# FX1 register map
Vendor: FTEL; File version: VP_FX1_V3.0_ISP_1.07
Registers are 32-bit, read-write, reset 0x0 unless marked. A register's access mark holds for its fields unless they carry their own. Offsets are from the block's base; [hi:lo] are bit positions; {n}, {i} and the like mark numbered series; 'fields as' and 'values as' point back to an identical list.

## MIPI_CSI2 — MIPI CSI-2 RX Controller (FTEL MAS v1.4 / HAS v1.2, CSR v1.4). Chỉ có khi VP bật --camera. Base là placeholder VP; 4 KiB aperture, giải mã 0x00-0xFF, 0x100-0xFFF trả DECERR. Lệch so với VP fx1_csi2_regs.h (workbook cũ): IP_VERSION, STREAM_CONFIG reset/bit2, BUFFER_STATUS bit19, DMA_ATTR reset, META_AREA_SIZE, TPG_CONTROL[5:4].
Base 0x11040000
0x00 IP_VERSION ro reset 0x10200 — IP identifier and version: major [31:16], minor [15:8], patch [7:0]. [access=ro]
  [31:0] IP_VERSION — 0x0001_0200 = v1.2.0 (MAS v1.4 param IP_VERSION). [access=ro]
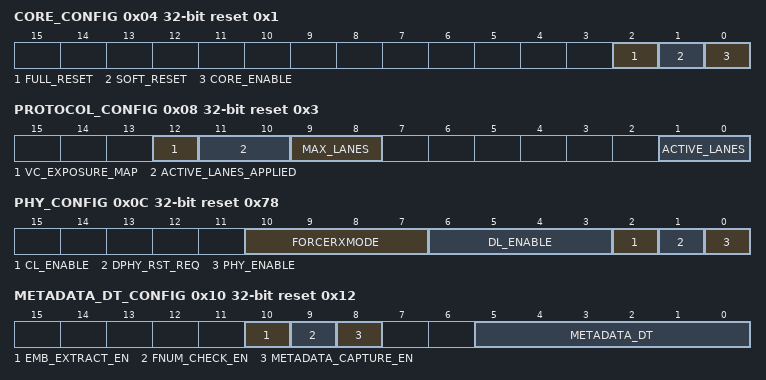
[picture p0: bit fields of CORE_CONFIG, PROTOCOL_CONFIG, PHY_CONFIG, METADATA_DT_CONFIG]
0x04 CORE_CONFIG reset 0x1 — Core control. [access=mixed]
  [2] FULL_RESET wo — Self-clearing. Resets D-PHY + datapath + register file via PHY Reset Sequencer. [access=wo]
  [1] SOFT_RESET — Level datapath reset, config preserved. Needs running rxbyteclkhs to reach Lane Mgmt. [access=rw]
  [0] CORE_ENABLE — Global core enable. Low: Packet FSM idle, per-VC context cleared, open captures dropped. [access=rw]
0x08 PROTOCOL_CONFIG reset 0x3 — Protocol configuration. [access=mixed]
  [12] VC_EXPOSURE_MAP — 0: VC0=Long, VC1=Short; 1: swapped. Applied to TID and lead channel. [access=rw]
  [11:10] ACTIVE_LANES_APPLIED ro — Lane count in use inside the datapath (read-back). [access=ro]
  [9:8] MAX_LANES ro — Build parameter MAX_LANES (reads parameter; counted as 0 in reset value). [access=ro]
  [1:0] ACTIVE_LANES — 00=1 lane, 01=2 lanes, 11=4 lanes, 10 reserved. Adopted only in Lane Mgmt ST_IDLE. [access=rw]
0x0C PHY_CONFIG reset 0x78 — D-PHY configuration. [access=mixed]
  [10:7] FORCERXMODE — Per-lane force-receive-mode, debug/bring-up only. [access=rw]
  [6:3] DL_ENABLE — Data-lane enables, bit 3 = lane 0 .. bit 6 = lane 3. [access=rw]
  [2] CL_ENABLE — Clock-lane enable. [access=rw]
  [1] DPHY_RST_REQ wo — Self-clearing. Starts PHY Reset Sequencer (phy_core_rst >= 40 core_clk). [access=wo]
  [0] PHY_ENABLE — D-PHY enable; when 0, cl_enable and all dl_enable outputs are deasserted. [access=rw]
0x10 METADATA_DT_CONFIG reset 0x12 — Metadata Data Type configuration. [access=rw]
  [10] EMB_EXTRACT_EN — Enable embedded-data field extractor. [access=rw]
  [9] FNUM_CHECK_EN — Enable frame-number sequence check. [access=rw]
  [8] METADATA_CAPTURE_EN — Enable embedded-data routing/capture. [access=rw]
  [5:0] METADATA_DT — Data Type routed to embedded-data path. Must not be 0x10/0x11/0x2B/0x2C. [access=rw]
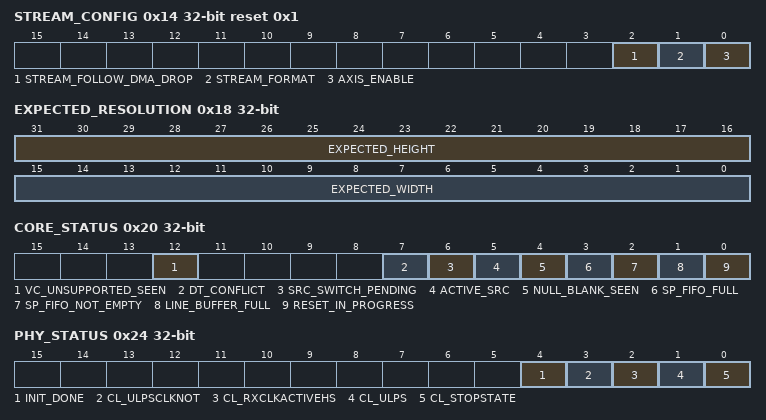
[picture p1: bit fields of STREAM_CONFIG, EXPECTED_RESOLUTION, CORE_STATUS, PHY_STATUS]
0x14 STREAM_CONFIG reset 0x1 — Stream output configuration. [access=rw]
  [2] STREAM_FOLLOW_DMA_DROP — 1: a capture dropped by DMA alone is also skipped on the stream path. [access=rw]
  [1] STREAM_FORMAT — 0 = packed RAW10/RAW12 (bypass), 1 = RAW16. Change only while AXIS_ENABLE = 0. [access=rw]
  [0] AXIS_ENABLE — Enable AXI4-Stream path towards the ISP. [access=rw]
0x18 EXPECTED_RESOLUTION — Expected resolution, reference of the resolution check. [access=rw]
  [31:16] EXPECTED_HEIGHT — Expected active height (lines). [access=rw]
  [15:0] EXPECTED_WIDTH — Expected active width (pixels). [access=rw]
0x20 CORE_STATUS ro — Core status. [access=ro]
  [12] VC_UNSUPPORTED_SEEN — Sticky: packet on unsupported Virtual Channel dropped. [access=ro]
  [7] DT_CONFLICT — Sticky: METADATA_DT programmed to a fixed-meaning Data Type. [access=ro]
  [6] SRC_SWITCH_PENDING — Source switch in progress. [access=ro]
  [5] ACTIVE_SRC — 0 = sensor path, 1 = TPG. [access=ro]
  [4] NULL_BLANK_SEEN — Sticky: Null/Blanking long packet dropped. [access=ro]
  [3] SP_FIFO_FULL — Generic Short Packet FIFO full. [access=ro]
  [2] SP_FIFO_NOT_EMPTY — Generic Short Packet FIFO not empty. [access=ro]
  [1] LINE_BUFFER_FULL — Line Buffer fill >= FULL_WATERMARK (raw level). [access=ro]
  [0] RESET_IN_PROGRESS — PHY Reset Sequencer running or SOFT_RESET set. [access=ro]
0x24 PHY_STATUS ro — D-PHY clock lane status. [access=ro]
  [4] INIT_DONE — D-PHY initialisation done (observability only). [access=ro]
  [3] CL_ULPSCLKNOT — Clock lane ULPS line indication (reads 1 in ULPS). [access=ro]
  [2] CL_RXCLKACTIVEHS — HS clock active (rxbyteclkhs running). [access=ro]
  [1] CL_ULPS — Clock lane in ULPS (inverse of cl_ulpsactivenot). [access=ro]
  [0] CL_STOPSTATE — Clock lane in Stop State. [access=ro]
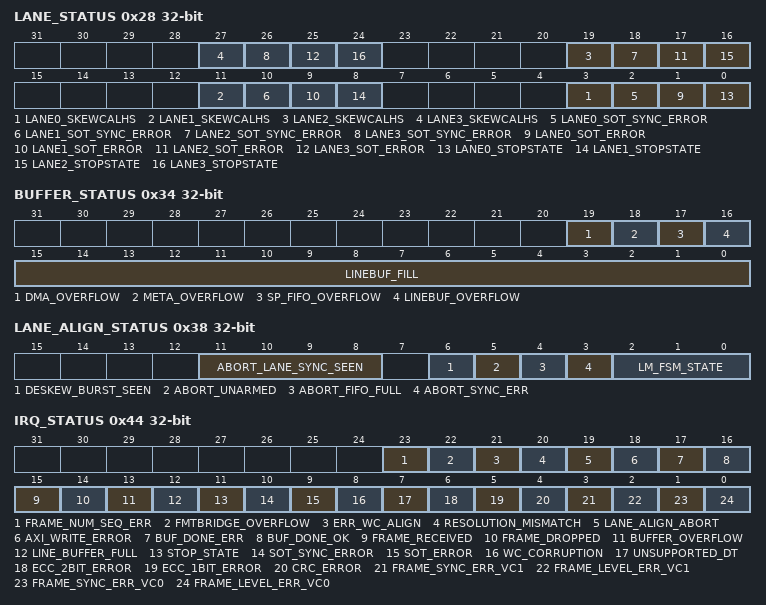
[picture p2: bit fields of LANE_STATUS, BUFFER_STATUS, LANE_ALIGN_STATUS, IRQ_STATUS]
0x28 LANE_STATUS ro — Per-lane status, lane x at bits [8x+3:8x]. SOT errors sticky, cleared by SOFT_RESET. [access=ro]
  [8n+3] LANE{n}_SKEWCALHS (n=0..3) — Lane {n} receiving deskew calibration. [access=ro]
  [8n+2] LANE{n}_SOT_SYNC_ERROR (n=0..3) — Lane {n} errsotsynchs seen (sticky). [access=ro]
  [8n+1] LANE{n}_SOT_ERROR (n=0..3) — Lane {n} errsoths seen (sticky). [access=ro]
  [8n] LANE{n}_STOPSTATE (n=0..3) — Lane {n} in Stop State. [access=ro]
0x2C PACKET_COUNT ro — Long packets whose header passed ECC; wraps at 2^32. [access=ro]
  [31:0] PACKET_COUNT — [access=ro]
0x30 FRAME_COUNT ro — Captures that have ended, dropped or not. [access=ro]
  [31:0] FRAME_COUNT — [access=ro]
0x34 BUFFER_STATUS ro — Buffer status; overflow bits sticky, cleared by reset only. [access=ro]
  [19] DMA_OVERFLOW — DMA RAW FIFO/line/region overflow (MAS v1.4). [access=ro]
  [18] META_OVERFLOW — Embedded payload word lost on metadata path. [access=ro]
  [17] SP_FIFO_OVERFLOW — Generic short packet dropped on full FIFO. [access=ro]
  [16] LINEBUF_OVERFLOW — Line Buffer write refused. [access=ro]
  [15:0] LINEBUF_FILL — Line Buffer fill level (0..2048). [access=ro]
0x38 LANE_ALIGN_STATUS ro — Lane alignment status. [access=ro]
  [11:8] ABORT_LANE_SYNC_SEEN — Per-lane sync_seen snapshot at abort; 0 = failing lane. [access=ro]
  [6] DESKEW_BURST_SEEN — Sticky: deskew burst classified and skipped. [access=ro]
  [5] ABORT_UNARMED — Last abort caused by burst closing while unarmed. [access=ro]
  [4] ABORT_FIFO_FULL — Last abort caused by PHY Delay FIFO full while unarmed. [access=ro]
  [3] ABORT_SYNC_ERR — Last abort caused by errsotsynchs. [access=ro]
  [2:0] LM_FSM_STATE — Burst FSM: 0 IDLE, 1 ARMING, 2 ALIGNED, 3 DRAIN, 4 ABORT. [access=ro]
0x40 GLOBAL_IRQ_ENABLE — Global interrupt enable. [access=rw]
  [0] GLOBAL_ENABLE — Master enable of csi2_irq. [access=rw]
0x44 IRQ_STATUS write-1-clears — Interrupt status, 24 sources, write 1 to clear; set wins over clear. Write response held until cleared bits read 0 (<= IRQ_CLR_TIMEOUT). [access=w1c]
  [23] FRAME_NUM_SEQ_ERR write-1-clears — Sensor frame number did not advance by one. [access=w1c]
  [22] FMTBRIDGE_OVERFLOW write-1-clears — Format Bridge output beat lost. [access=w1c]
  [21] ERR_WC_ALIGN write-1-clears — Line ended mid pixel-packing unit. [access=w1c]
  [20] RESOLUTION_MISMATCH write-1-clears — Frame geometry differs from EXPECTED_RESOLUTION. [access=w1c]
  [19] LANE_ALIGN_ABORT write-1-clears — Lane Management discarded a burst. [access=w1c]
  [18] AXI_WRITE_ERROR write-1-clears — DMA write got SLVERR/DECERR. [access=w1c]
  [17] BUF_DONE_ERR write-1-clears — Ping-pong buffer released as SW_OWNED_ERROR. [access=w1c]
  [16] BUF_DONE_OK write-1-clears — Ping-pong buffer released as SW_OWNED_VALID. [access=w1c]
  [15] FRAME_RECEIVED write-1-clears — Capture ended and delivered on stream path. [access=w1c]
  [14] FRAME_DROPPED write-1-clears — Capture not delivered on every enabled path. [access=w1c]
  [13] BUFFER_OVERFLOW write-1-clears — Line buffer/SP FIFO/metadata/DMA overflow; see BUFFER_STATUS. [access=w1c]
  [12] LINE_BUFFER_FULL write-1-clears — Line Buffer reached watermark (sensor path only). [access=w1c]
  [11] STOP_STATE write-1-clears — Clock lane entered Stop State. [access=w1c]
  [10] SOT_SYNC_ERROR write-1-clears — errsotsynchs on any lane. [access=w1c]
  [9] SOT_ERROR write-1-clears — errsoths on any lane. [access=w1c]
  [8] WC_CORRUPTION write-1-clears — Burst ended with non-zero remaining byte count. [access=w1c]
  [7] UNSUPPORTED_DT write-1-clears — Long packet with unsupported Data Type. [access=w1c]
  [6] ECC_2BIT_ERROR write-1-clears — Uncorrectable header ECC error. [access=w1c]
  [5] ECC_1BIT_ERROR write-1-clears — Header single-bit ECC error corrected. [access=w1c]
  [4] CRC_ERROR write-1-clears — Payload CRC-16 mismatch. [access=w1c]
  [3] FRAME_SYNC_ERR_VC1 write-1-clears — VC1 frame identification failure. [access=w1c]
  [2] FRAME_LEVEL_ERR_VC1 write-1-clears — VC1 frame had CRC/WC/lane-abort error (at Frame End). [access=w1c]
  [1] FRAME_SYNC_ERR_VC0 write-1-clears — VC0 frame identification failure. [access=w1c]
  [0] FRAME_LEVEL_ERR_VC0 write-1-clears — VC0 frame had CRC/WC/lane-abort error (at Frame End). [access=w1c]
0x48 IRQ_ENABLE — Per-source interrupt mask, mirrors IRQ_STATUS. [access=rw]
  [23:0] IRQ_ENABLE_MASK — [access=rw]
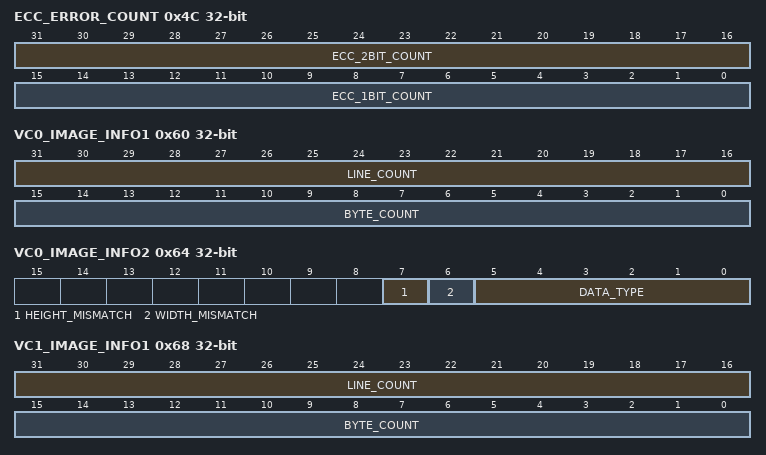
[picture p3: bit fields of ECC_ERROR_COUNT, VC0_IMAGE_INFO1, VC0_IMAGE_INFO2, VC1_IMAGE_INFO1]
0x4C ECC_ERROR_COUNT ro — ECC error counters, each saturating at 0xFFFF. [access=ro]
  [31:16] ECC_2BIT_COUNT — [access=ro]
  [15:0] ECC_1BIT_COUNT — [access=ro]
0x50 CRC_ERROR_COUNT ro — Payload CRC-16 error count, saturating. [access=ro]
  [31:0] CRC_ERROR_COUNT — [access=ro]
0x54 FRAME_DROP_COUNT ro — Dropped capture count, saturating. [access=ro]
  [31:0] FRAME_DROP_COUNT — [access=ro]
0x58 LANE_ABORT_COUNT ro — Bursts discarded by Lane Management, saturating at 0xFFFF. [access=ro]
  [15:0] LANE_ABORT_COUNT — [access=ro]
0x60 VC0_IMAGE_INFO1 ro — Geometry of last published frame on VC0. [access=ro]
  [31:16] LINE_COUNT — Image lines of the frame. [access=ro]
  [15:0] BYTE_COUNT — Payload bytes of one image long packet (last line). [access=ro]
0x64 VC0_IMAGE_INFO2 ro — Data Type and resolution check of last published frame on VC0. [access=ro]
  [7] HEIGHT_MISMATCH — [access=ro]
  [6] WIDTH_MISMATCH — [access=ro]
  [5:0] DATA_TYPE — [access=ro]
0x68 VC1_IMAGE_INFO1 ro — Geometry of last published frame on VC1. [access=ro]
  fields as VC0_IMAGE_INFO1
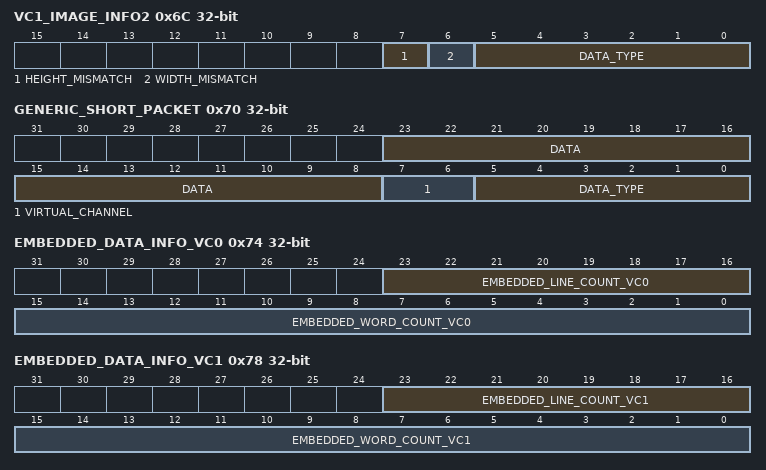
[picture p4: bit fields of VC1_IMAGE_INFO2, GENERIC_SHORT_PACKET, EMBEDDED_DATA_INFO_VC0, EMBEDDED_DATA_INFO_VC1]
0x6C VC1_IMAGE_INFO2 ro — Data Type and resolution check of last published frame on VC1. [access=ro]
  fields as VC0_IMAGE_INFO2
0x70 GENERIC_SHORT_PACKET ro — Head of generic short-packet FIFO (DT 0x08..0x0F). Read pops the entry; empty FIFO reads 0. [access=ro]
  [23:8] DATA — [access=ro]
  [7:6] VIRTUAL_CHANNEL — [access=ro]
  [5:0] DATA_TYPE — [access=ro]
0x74 EMBEDDED_DATA_INFO_VC0 ro — Embedded-data accounting, last published frame on VC0. [access=ro]
  [23:16] EMBEDDED_LINE_COUNT_VC0 — [access=ro]
  [15:0] EMBEDDED_WORD_COUNT_VC0 — [access=ro]
0x78 EMBEDDED_DATA_INFO_VC1 ro — Embedded-data accounting, last published frame on VC1. [access=ro]
  [23:16] EMBEDDED_LINE_COUNT_VC1 — [access=ro]
  [15:0] EMBEDDED_WORD_COUNT_VC1 — [access=ro]
0x7C METADATA_RECORD_ID — Software handle written into the metadata record; sampled when a capture opens. [access=rw]
  [31:0] METADATA_RECORD_ID — [access=rw]
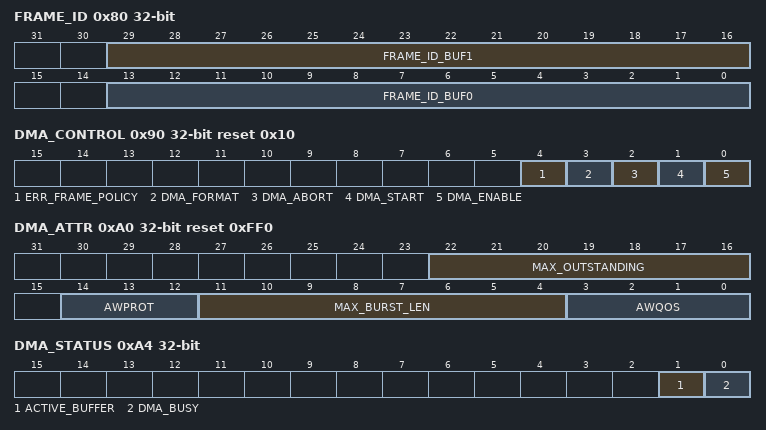
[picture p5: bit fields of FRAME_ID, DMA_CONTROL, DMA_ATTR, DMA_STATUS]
0x80 FRAME_ID ro — frame_id of the capture held in each ping-pong buffer. [access=ro]
  [29:16] FRAME_ID_BUF1 — [access=ro]
  [13:0] FRAME_ID_BUF0 — [access=ro]
0x84 TIMESTAMP_LO ro — Timestamp [31:0] of last published capture (ns). Read snapshots HI into a shadow; read LO first. [access=ro]
  [31:0] TIMESTAMP_LO — [access=ro]
0x88 TIMESTAMP_HI ro — Timestamp [63:32], from shadow taken at TIMESTAMP_LO read. [access=ro]
  [31:0] TIMESTAMP_HI — [access=ro]
0x90 DMA_CONTROL reset 0x10 — DMA control. [access=rw]
  [4] ERR_FRAME_POLICY — Sampled at claim. 0 = aborted buffer returns free; 1 = released SW_OWNED_ERROR. [access=rw]
  [3] DMA_FORMAT — 0 = packed RAW10/RAW12, 1 = RAW16. Change only while DMA_ENABLE=0 and idle. [access=rw]
  [2] DMA_ABORT — Level: no claim, every buffer in ST_WRITE aborted. [access=rw]
  [1] DMA_START — Allow buffer claims; clear first to stop gracefully. [access=rw]
  [0] DMA_ENABLE — Enable DMA path; clearing it aborts buffers in ST_WRITE. [access=rw]
0x94 DMA_BUFFER0_ADDR — DDR base of ping-pong buffer 0; bits [2:0] ignored. [access=rw]
  [31:0] DMA_BUFFER0_ADDR — [access=rw]
0x98 DMA_BUFFER1_ADDR — DDR base of ping-pong buffer 1; bits [2:0] ignored. [access=rw]
  [31:0] DMA_BUFFER1_ADDR — [access=rw]
0x9C DMA_BUFFER_SIZE — Size of the RAW region of one channel; buffer = 2*(this + META_AREA_SIZE). [access=rw]
  [31:0] DMA_BUFFER_SIZE — [access=rw]
0xA0 DMA_ATTR reset 0xFF0 — DMA AXI attributes; sampled at claim. [access=mixed]
  [22:16] MAX_OUTSTANDING ro — Read-back of build parameter MAX_OUTSTANDING (8). [access=ro]
  [14:12] AWPROT — m_axi4_awprot. [access=rw]
  [11:4] MAX_BURST_LEN — AWLEN encoding (beats-1), clamped to MAX_BURST_BEATS-1. [access=rw]
  [3:0] AWQOS — m_axi4_awqos. [access=rw]
0xA4 DMA_STATUS ro — DMA status. [access=ro]
  [1] ACTIVE_BUFFER — Buffer most recently claimed. [access=ro]
  [0] DMA_BUSY — Any buffer in WRITE/DRAIN/ABORT. [access=ro]
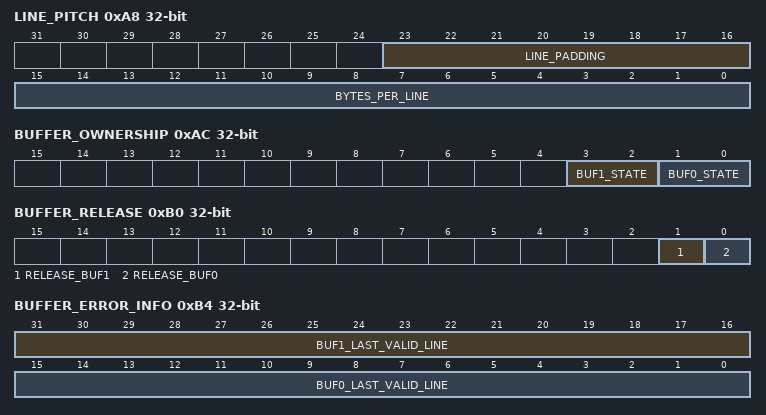
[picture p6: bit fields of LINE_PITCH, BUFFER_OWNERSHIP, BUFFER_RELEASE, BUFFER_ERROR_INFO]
0xA8 LINE_PITCH — Line pitch in DDR; stride = BYTES_PER_LINE + LINE_PADDING (multiple of 8). [access=rw]
  [23:16] LINE_PADDING — [access=rw]
  [15:0] BYTES_PER_LINE — [access=rw]
0xAC BUFFER_OWNERSHIP ro — Per-buffer ownership: 00 HW_OWNED, 01 SW_OWNED_VALID, 10 SW_OWNED_ERROR. [access=ro]
  [3:2] BUF1_STATE — [access=ro]
  [1:0] BUF0_STATE — [access=ro]
0xB0 BUFFER_RELEASE wo — Write 1 to return a software-owned buffer to the DMA. [access=wo]
  [1] RELEASE_BUF1 — [access=wo]
  [0] RELEASE_BUF0 — [access=wo]
0xB4 BUFFER_ERROR_INFO ro — Last line (from 0) written OKAY per buffer; 0xFFFF if none. [access=ro]
  [31:16] BUF1_LAST_VALID_LINE — [access=ro]
  [15:0] BUF0_LAST_VALID_LINE — [access=ro]
0xB8 META_AREA_SIZE — Size of one channel's metadata area (>= 0x80 + max embedded payload). MAS v1.4. [access=rw]
  [31:0] META_AREA_SIZE — [access=rw]
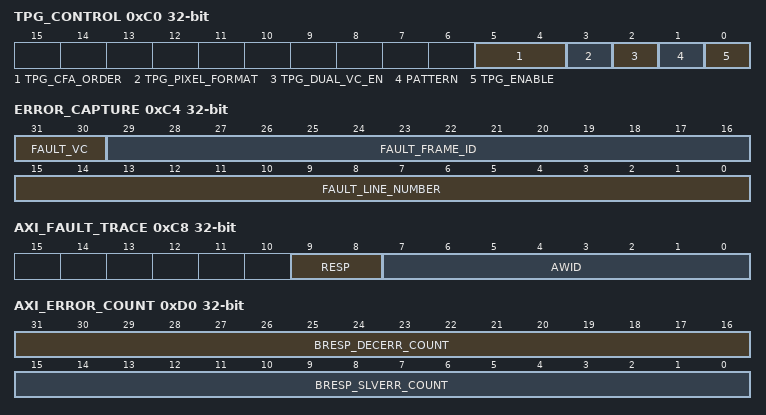
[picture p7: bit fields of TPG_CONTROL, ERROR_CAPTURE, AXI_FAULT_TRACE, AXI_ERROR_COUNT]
0xC0 TPG_CONTROL — Test Pattern Generator control; fields except TPG_ENABLE apply from next frame. [access=rw]
  [5:4] TPG_CFA_ORDER — 00 RGGB, 01 GRBG, 10 GBRG, 11 BGGR (MAS v1.4). [access=rw]
  [3] TPG_PIXEL_FORMAT — 0 = RAW12, 1 = RAW10. [access=rw]
  [2] TPG_DUAL_VC_EN — Interleave VC0/VC1 lines. [access=rw]
  [1] PATTERN — 0 = vertical bars, 1 = horizontal bars. [access=rw]
  [0] TPG_ENABLE — Start TPG and select it as video source (TPG Mux). [access=rw]
0xC4 ERROR_CAPTURE ro — First protocol error of newest capture with an error; cleared by SOFT_RESET. [access=ro]
  [31:30] FAULT_VC — 00 VC0, 01 VC1, 11 unknown. [access=ro]
  [29:16] FAULT_FRAME_ID — frame_id of the capture; 0 = nothing captured. [access=ro]
  [15:0] FAULT_LINE_NUMBER — Lines completed on that channel; 0xFFFF if channel unknown. [access=ro]
0xC8 AXI_FAULT_TRACE ro — First faulting AXI write since last soft reset. [access=ro]
  [9:8] RESP — [access=ro]
  [7:0] AWID — [access=ro]
0xCC AXI_FAULT_ADDR ro — Address of first faulting AXI write since last soft reset. [access=ro]
  [31:0] FAULT_AWADDR — [access=ro]
0xD0 AXI_ERROR_COUNT ro — SLVERR/DECERR write-response counters, saturating. [access=ro]
  [31:16] BRESP_DECERR_COUNT — [access=ro]
  [15:0] BRESP_SLVERR_COUNT — [access=ro]
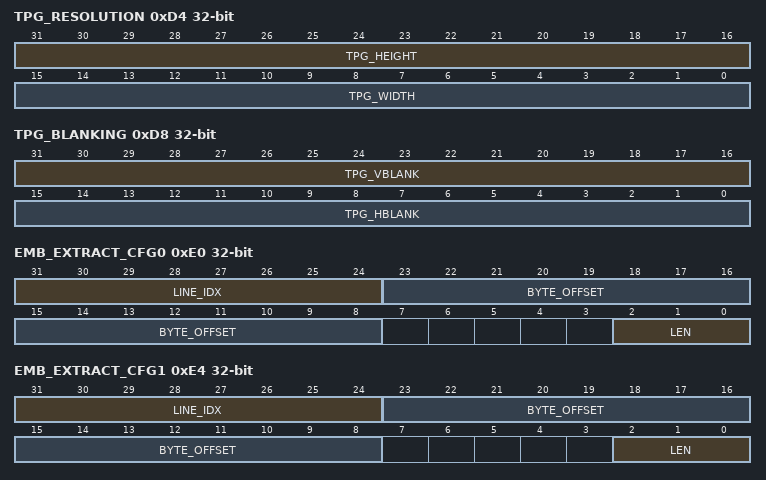
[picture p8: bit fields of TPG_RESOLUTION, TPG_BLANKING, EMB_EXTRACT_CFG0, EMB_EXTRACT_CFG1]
0xD4 TPG_RESOLUTION — TPG active size; width truncated to multiple of 4, min 8x8. [access=rw]
  [31:16] TPG_HEIGHT — Lines per Virtual Channel. [access=rw]
  [15:0] TPG_WIDTH — [access=rw]
0xD8 TPG_BLANKING — TPG blanking. [access=rw]
  [31:16] TPG_VBLANK — Blank line-times after each frame. [access=rw]
  [15:0] TPG_HBLANK — sys_clk cycles after each line. [access=rw]
0xE0 EMB_EXTRACT_CFG0 — Extraction slot 0 descriptor. [access=rw]
  [31:24] LINE_IDX — Embedded line index. [access=rw]
  [23:8] BYTE_OFFSET — [access=rw]
  [2:0] LEN — Field length in bytes. [access=rw]
0xE4 EMB_EXTRACT_CFG1 — Extraction slot 1 descriptor. [access=rw]
  fields as EMB_EXTRACT_CFG0
0xE8 EMB_EXTRACT_VC0_VAL0 ro — Field captured by slot 0 on VC0 in last published frame. [access=ro]
  [31:0] VALUE — [access=ro]
0xEC EMB_EXTRACT_VC0_VAL1 ro — Field captured by slot 1 on VC0 in last published frame. [access=ro]
  [31:0] VALUE — [access=ro]
0xF0 EMB_EXTRACT_VC1_VAL0 ro — Field captured by slot 0 on VC1 in last published frame. [access=ro]
  [31:0] VALUE — [access=ro]
0xF4 EMB_EXTRACT_VC1_VAL1 ro — Field captured by slot 1 on VC1 in last published frame. [access=ro]
  [31:0] VALUE — [access=ro]
